# STM32WB10_CM4 register map
File version: 1.2
CPU: CM4 r0p1, little endian, MPU, FPU, 4 interrupt priority bits
Registers are 32-bit, read-write, reset 0x0 unless marked. A register's access mark holds for its fields unless they carry their own. Offsets are from the block's base; [hi:lo] are bit positions; {n}, {i} and the like mark numbered series; 'fields as' and 'values as' point back to an identical list.

## ADC — Analog to Digital Converter
Base 0x40012400
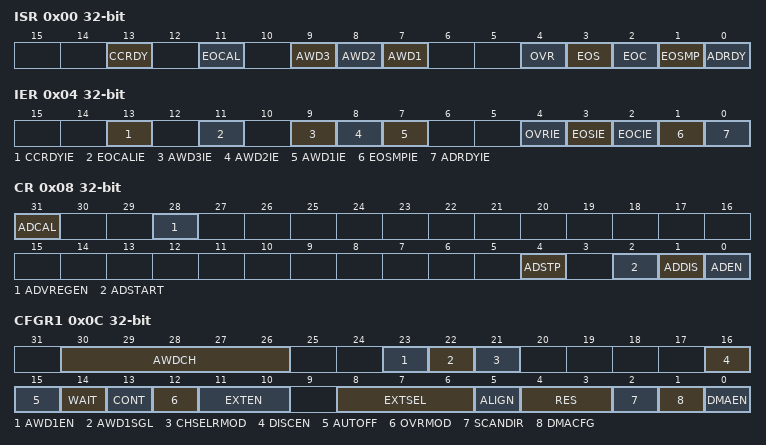
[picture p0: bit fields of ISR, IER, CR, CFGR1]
0x00 ISR — ADC interrupt and status register
  [13] CCRDY, [11] EOCAL, [9] AWD3, [8] AWD2, [7] AWD1, [4] OVR, [3] EOS, [2] EOC, [1] EOSMP, [0] ADRDY
0x04 IER — ADC interrupt enable register
  [13] CCRDYIE, [11] EOCALIE, [9] AWD3IE, [8] AWD2IE, [7] AWD1IE, [4] OVRIE, [3] EOSIE, [2] EOCIE, [1] EOSMPIE, [0] ADRDYIE
0x08 CR — ADC control register
  [31] ADCAL, [28] ADVREGEN, [4] ADSTP, [2] ADSTART, [1] ADDIS, [0] ADEN
0x0C CFGR1 — ADC configuration register 1
  [30:26] AWDCH — AWD1CH
  [23] AWD1EN
  [22] AWD1SGL
  [21] CHSELRMOD
  [16] DISCEN
  [15] AUTOFF
  [14] WAIT
  [13] CONT
  [12] OVRMOD
  [11:10] EXTEN
  [8:6] EXTSEL
  [5] ALIGN
  [4:3] RES
  [2] SCANDIR
  [1] DMACFG
  [0] DMAEN
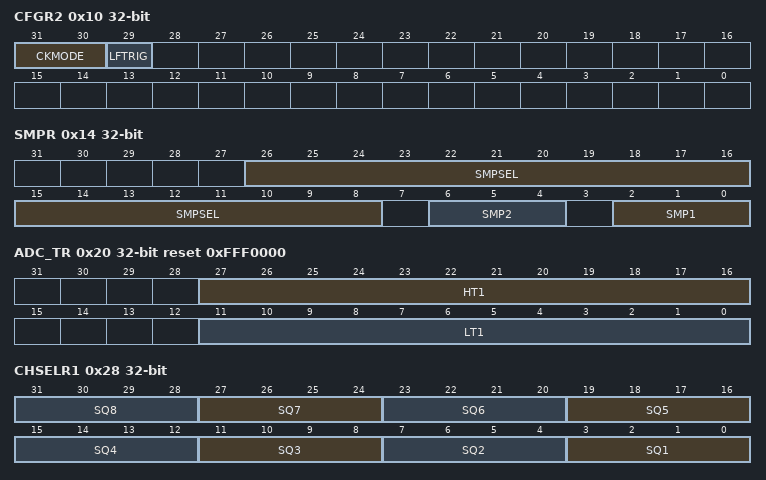
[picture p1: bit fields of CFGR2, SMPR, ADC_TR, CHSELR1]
0x10 CFGR2 — ADC configuration register 2
  [31:30] CKMODE, [29] LFTRIG
0x14 SMPR — ADC sampling time register
  [26:8] SMPSEL, [6:4] SMP2, [2:0] SMP1
0x20 ADC_TR reset 0xFFF0000 — ADC watchdog threshold register
  [27:16] HT1, [11:0] LT1
0x28 CHSELR0 — channel selection register
  [18:0] CHSEL
0x28 CHSELR1 (alternate view of CHSELR0) — channel selection register
  [4n-1:4n-4] SQ{n} (n=1..8)
0x40 DR ro — ADC data register
  [15:0] DATA
0xB4 CALFACT — ADC Calibration factor
  [6:0] CALFACT
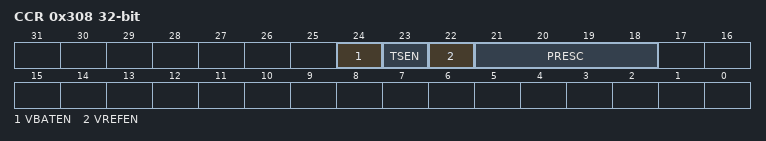
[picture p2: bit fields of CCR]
0x308 CCR — ADC common configuration register
  [24] VBATEN, [23] TSEN, [22] VREFEN, [21:18] PRESC

## CRC — Cyclic redundancy check calculation unit
Base 0x40023000
0x00 DR reset 0xFFFFFFFF — Data register
  [31:0] DR — Data register bits
0x04 IDR — Independent data register
  [31:0] IDR — General-purpose 32-bit data register bits
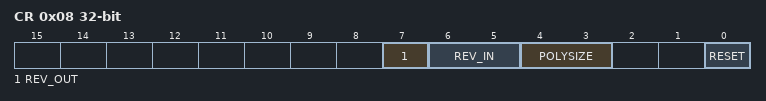
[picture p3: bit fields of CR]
0x08 CR — Control register
  [7] REV_OUT — Reverse output data
  [6:5] REV_IN — Reverse input data
  [4:3] POLYSIZE — Polynomial size
  [0] RESET — RESET bit
0x10 INIT reset 0xFFFFFFFF — Initial CRC value
  [31:0] CRC_INIT — Programmable initial CRC value
0x14 POL reset 0x4C11DB7 — polynomial
  [31:0] POL — Programmable polynomial

## DBGMCU — Debug support
Base 0xE0042000
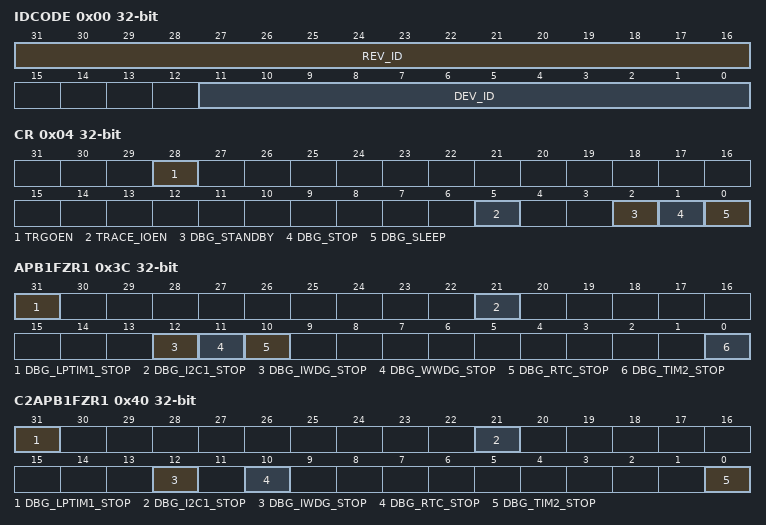
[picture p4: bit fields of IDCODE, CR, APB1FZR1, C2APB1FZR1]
0x00 IDCODE ro — MCU Device ID Code Register
  [31:16] REV_ID — Revision Identifier
  [11:0] DEV_ID — Device Identifier
0x04 CR — Debug MCU Configuration Register
  [28] TRGOEN — External trigger output enable
  [5] TRACE_IOEN — Trace port and clock enable
  [2] DBG_STANDBY — Debug Standby Mode
  [1] DBG_STOP — Debug Stop Mode
  [0] DBG_SLEEP — Debug Sleep Mode
0x3C APB1FZR1 — APB1 Low Freeze Register CPU1
  [31] DBG_LPTIM1_STOP — Debug LPTIM1 stopped when Core is halted
  [21] DBG_I2C1_STOP — Debug I2C1 SMBUS timeout stopped when Core is halted
  [12] DBG_IWDG_STOP — IWDG counter stopped when core is halted
  [11] DBG_WWDG_STOP — WWDG counter stopped when core is halted
  [10] DBG_RTC_STOP — RTC counter stopped when core is halted
  [0] DBG_TIM2_STOP — Debug Timer 2 stopped when Core is halted
0x40 C2APB1FZR1 — APB1 Low Freeze Register CPU2
  [31] DBG_LPTIM1_STOP — LPTIM1 counter stopped when core is halted
  [21] DBG_I2C1_STOP — I2C1 SMBUS timeout stopped when core is halted
  [12] DBG_IWDG_STOP — IWDG stopped when core is halted
  [10] DBG_RTC_STOP — RTC counter stopped when core is halted
  [0] DBG_TIM2_STOP — LPTIM2 counter stopped when core is halted
0x44 APB1FZR2 — APB1 High Freeze Register CPU1
  [5] DBG_LPTIM2_STOP — LPTIM2 counter stopped when core is halted
0x48 C2APB1FZR2 — APB1 High Freeze Register CPU2
  [5] DBG_LPTIM2_STOP — LPTIM2 counter stopped when core is halted
0x4C APB2FZR — APB2 Freeze Register CPU1
  [11] DBG_TIM1_STOP — TIM1 counter stopped when core is halted
0x50 C2APB2FZR (alternate view of C2APB1FZR2) — APB2 Freeze Register CPU2
  [11] DBG_TIM1_STOP — TIM1 counter stopped when core is halted

## DMA1 — Direct memory access controller
Base 0x40020000
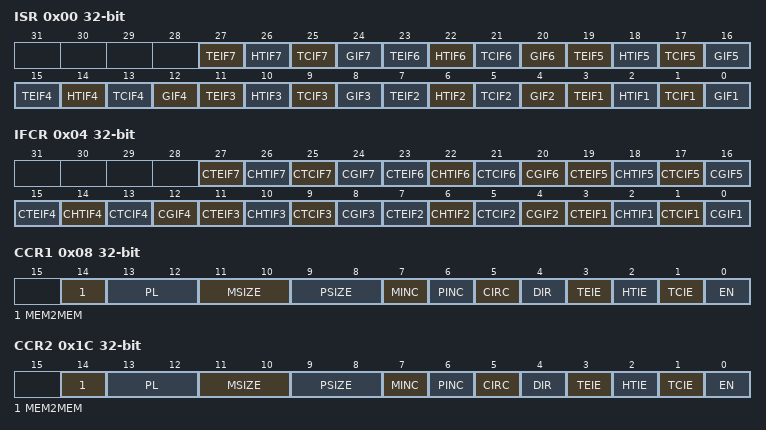
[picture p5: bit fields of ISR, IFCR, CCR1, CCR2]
0x00 ISR ro — interrupt status register
  [4n-1] TEIF{n} (n=1..7) — Channel x transfer error flag (x = 1 ..7)
  [4n-2] HTIF{n} (n=1..7) — Channel x half transfer flag (x = 1 ..7)
  [4n-3] TCIF{n} (n=1..7) — Channel x transfer complete flag (x = 1 ..7)
  [4n-4] GIF{n} (n=1..7) — Channel x global interrupt flag (x = 1 ..7)
0x04 IFCR wo — interrupt flag clear register
  [4n-1] CTEIF{n} (n=1..7) — Channel x transfer error clear (x = 1 ..7)
  [4n-2] CHTIF{n} (n=1..7) — Channel x half transfer clear (x = 1 ..7)
  [4n-3] CTCIF{n} (n=1..7) — Channel x transfer complete clear (x = 1 ..7)
  [4n-4] CGIF{n} (n=1..7) — Channel x global interrupt clear (x = 1 ..7)
0x08 CCR1 — channel x configuration register
  [14] MEM2MEM — Memory to memory mode
  [13:12] PL — Channel priority level
  [11:10] MSIZE — Memory size
  [9:8] PSIZE — Peripheral size
  [7] MINC — Memory increment mode
  [6] PINC — Peripheral increment mode
  [5] CIRC — Circular mode
  [4] DIR — Data transfer direction
  [3] TEIE — Transfer error interrupt enable
  [2] HTIE — Half transfer interrupt enable
  [1] TCIE — Transfer complete interrupt enable
  [0] EN — Channel enable
0x0C CNDTR1 — channel x number of data register
  [15:0] NDT — Number of data to transfer
0x10 CPAR1 — channel x peripheral address register
  [31:0] PA — Peripheral address
{0x0+0x14*i} CMAR{i} (i=1..7) — channel x memory address register
  [31:0] MA — Memory address
0x1C CCR2 — channel x configuration register
  fields as CCR1
0x20 CNDTR2 — channel x number of data register
  [15:0] NDT — Number of data to transfer
0x24 CPAR2 — channel x peripheral address register
  [31:0] PA — Peripheral address
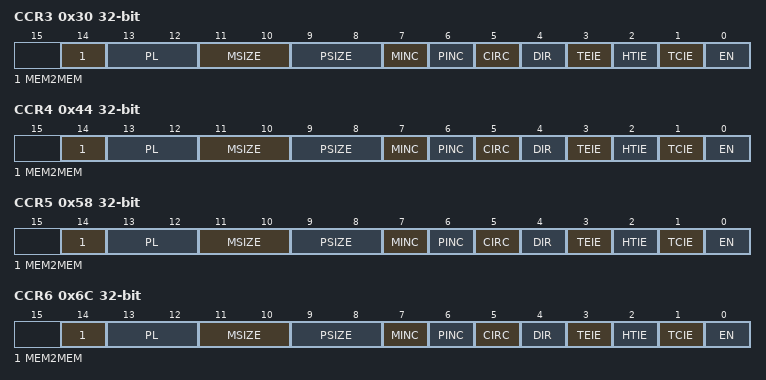
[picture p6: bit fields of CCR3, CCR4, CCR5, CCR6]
0x30 CCR3 — channel x configuration register
  fields as CCR1
0x34 CNDTR3 — channel x number of data register
  [15:0] NDT — Number of data to transfer
0x38 CPAR3 — channel x peripheral address register
  [31:0] PA — Peripheral address
0x44 CCR4 — channel x configuration register
  fields as CCR1
0x48 CNDTR4 — channel x number of data register
  [15:0] NDT — Number of data to transfer
0x4C CPAR4 — channel x peripheral address register
  [31:0] PA — Peripheral address
0x58 CCR5 — channel x configuration register
  fields as CCR1
0x5C CNDTR5 — channel x number of data register
  [15:0] NDT — Number of data to transfer
0x60 CPAR5 — channel x peripheral address register
  [31:0] PA — Peripheral address
0x6C CCR6 — channel x configuration register
  fields as CCR1
0x70 CNDTR6 — channel x number of data register
  [15:0] NDT — Number of data to transfer
0x74 CPAR6 — channel x peripheral address register
  [31:0] PA — Peripheral address
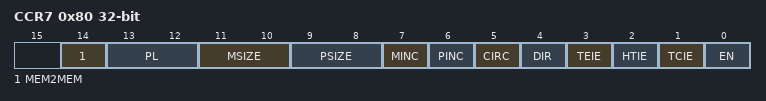
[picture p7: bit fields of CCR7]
0x80 CCR7 — channel x configuration register
  fields as CCR1
0x84 CNDTR7 — channel x number of data register
  [15:0] NDT — Number of data to transfer
0x88 CPAR7 — channel x peripheral address register
  [31:0] PA — Peripheral address

## Notices in the file
Copyright (c) 2021 STMicroelectronics.
SPDX-License-Identifier: Apache-2.0
Licensed under the Apache License, Version 2.0 (the "License");
you may not use this file except in compliance with the License.
You may obtain a copy of the License at
http://www.apache.org/licenses/LICENSE-2.0
Unless required by applicable law or agreed to in writing, software
distributed under the License is distributed on an "AS IS" BASIS,
WITHOUT WARRANTIES OR CONDITIONS OF ANY KIND, either express or implied.
See the License for the specific language governing permissions and
limitations under the License.
